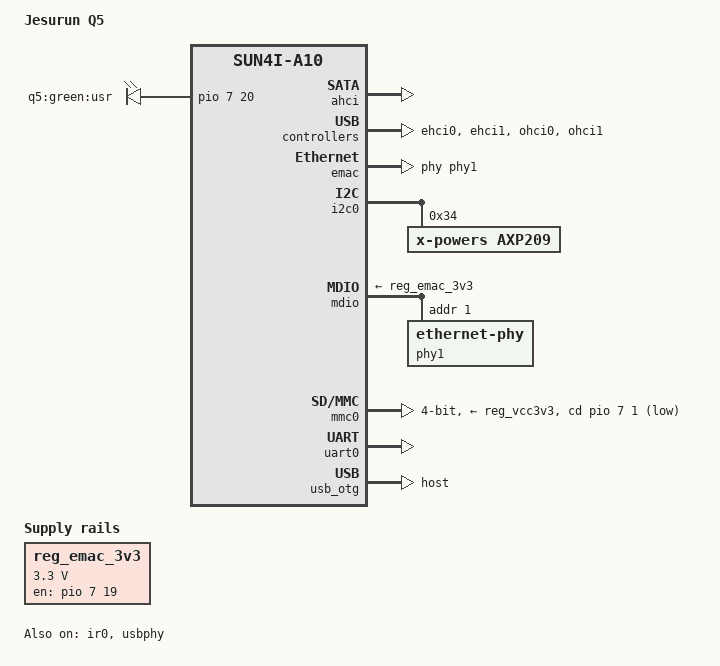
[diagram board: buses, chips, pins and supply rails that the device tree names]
/dts-v1/;
#include "sun4i-a10.dtsi"
#include "sunxi-common-regulators.dtsi"
#include <dt-bindings/gpio/gpio.h>
/ {
	model = "Jesurun Q5";
	compatible = "jesurun,q5", "allwinner,sun4i-a10";
	aliases {
		serial0 = &uart0;
	};
	chosen {
		stdout-path = "serial0:115200n8";
	};
	leds {
		compatible = "gpio-leds";
		led {
			label = "q5:green:usr";
			gpios = <&pio 7 20 GPIO_ACTIVE_HIGH>;   
		};
	};
	reg_emac_3v3: emac-3v3 {
		compatible = "regulator-fixed";
		regulator-name = "emac-3v3";
		regulator-min-microvolt = <3300000>;
		regulator-max-microvolt = <3300000>;
		startup-delay-us = <20000>;
		enable-active-high;
		gpio = <&pio 7 19 GPIO_ACTIVE_HIGH>;    
	};
};
&ahci {
	status = "okay";
};
&ehci0 {
	status = "okay";
};
&ehci1 {
	status = "okay";
};
&emac {
	phy-handle = <&phy1>;
	status = "okay";
};
&emac_sram {
	status = "okay";
};
&i2c0 {
	status = "okay";
	axp209: pmic@34 {
		compatible = "x-powers,axp209";
		reg = <0x34>;
		interrupts = <0>;
		interrupt-controller;
		#interrupt-cells = <1>;
	};
};
&ir0 {
	pinctrl-names = "default";
	pinctrl-0 = <&ir0_rx_pins>;
	status = "okay";
};
&mdio {
	phy-supply = <&reg_emac_3v3>;
	status = "okay";
	phy1: ethernet-phy@1 {
		reg = <1>;
	};
};
&mmc0 {
	vmmc-supply = <&reg_vcc3v3>;
	bus-width = <4>;
	cd-gpios = <&pio 7 1 GPIO_ACTIVE_LOW>;  
	status = "okay";
};
&ohci0 {
	status = "okay";
};
&ohci1 {
	status = "okay";
};
&otg_sram {
	status = "okay";
};
&reg_usb0_vbus {
	regulator-boot-on;
	status = "okay";
};
&reg_usb1_vbus {
	status = "okay";
};
&reg_usb2_vbus {
	status = "okay";
};
&uart0 {
	pinctrl-names = "default";
	pinctrl-0 = <&uart0_pb_pins>;
	status = "okay";
};
&usb_otg {
	dr_mode = "host";
	status = "okay";
};
&usbphy {
	usb0_vbus-supply = <&reg_usb0_vbus>;
	usb1_vbus-supply = <&reg_usb1_vbus>;
	usb2_vbus-supply = <&reg_usb2_vbus>;
	status = "okay";
};
